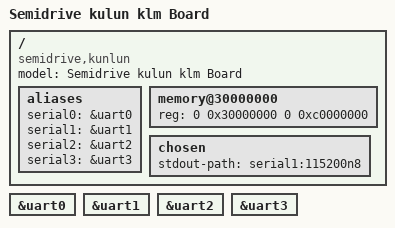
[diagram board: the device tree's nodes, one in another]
/*
 * Spreadtrum SC9836 openphone board DTS file
 *
 * Copyright (C) 2014, Spreadtrum Communications Inc.
 *
 * This file is licensed under a dual GPLv2 or X11 license.
 */

/dts-v1/;

#include "klm.dtsi"

/ {
	model = "Semidrive kulun klm Board";

	compatible = "semidrive,kunlun";

	aliases {
		serial0 = &uart0;
		serial1 = &uart1;
		serial2 = &uart2;
		serial3 = &uart3;
	};

	memory@30000000 {
		device_type = "memory";
		reg = <0 0x30000000 0 0xc0000000>;
	};

	chosen {
		stdout-path = "serial1:115200n8";
	};
};

&uart0 {
	status = "okay";
};

&uart1 {
	status = "okay";
};

&uart2 {
	status = "okay";
};

&uart3 {
	status = "okay";
};
